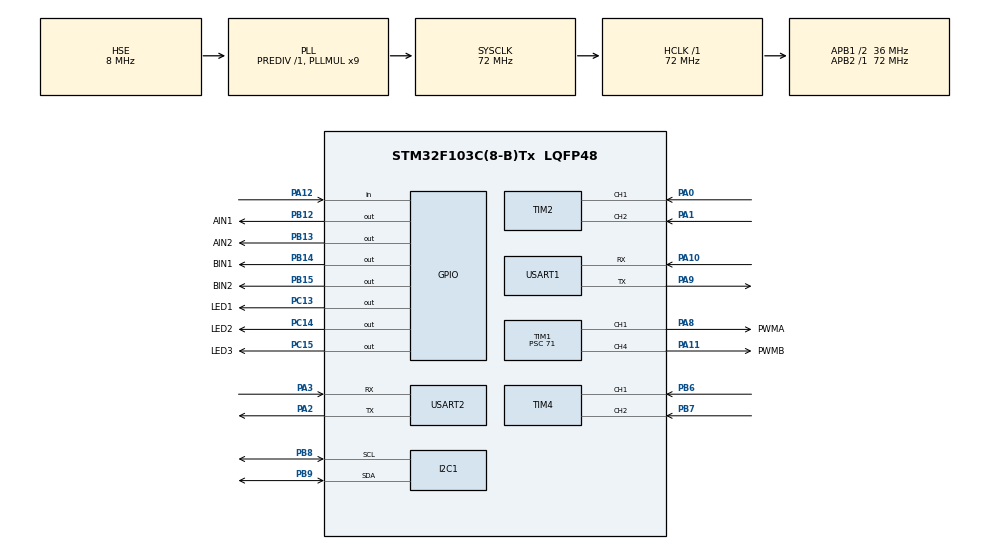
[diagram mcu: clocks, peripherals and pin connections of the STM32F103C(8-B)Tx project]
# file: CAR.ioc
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Mcu.Family=STM32F1
Mcu.Name=STM32F103C(8-B)Tx
Mcu.Package=LQFP48
NVIC.PriorityGroup=NVIC_PRIORITYGROUP_4
NVIC.TIM2_IRQn=true\:3\:0\:true\:false\:true\:true\:true
NVIC.TIM3_IRQn=true\:1\:0\:true\:false\:true\:true\:true
NVIC.TIM4_IRQn=true\:3\:0\:true\:false\:true\:true\:true
PA0-WKUP.Signal=S_TIM2_CH1_ETR
PA1.Signal=S_TIM2_CH2
PA10.Mode=Asynchronous
PA10.Signal=USART1_RX
PA11.GPIO_Label=PWMB
PA11.Signal=S_TIM1_CH4
PA12.Signal=GPIO_Input
PA13.Mode=Serial_Wire
PA13.Signal=SYS_JTMS-SWDIO
PA14.Mode=Serial_Wire
PA14.Signal=SYS_JTCK-SWCLK
PA2.Mode=Asynchronous
PA2.Signal=USART2_TX
PA3.Mode=Asynchronous
PA3.Signal=USART2_RX
PA8.GPIO_Label=PWMA
PA8.Signal=S_TIM1_CH1
PA9.Mode=Asynchronous
PA9.Signal=USART1_TX
PB12.GPIO_Label=AIN1
PB12.GPIO_Speed=GPIO_SPEED_FREQ_MEDIUM
PB12.Signal=GPIO_Output
PB13.GPIO_Label=AIN2
PB13.GPIO_Speed=GPIO_SPEED_FREQ_MEDIUM
PB13.Signal=GPIO_Output
PB14.GPIO_Label=BIN1
PB14.GPIO_Speed=GPIO_SPEED_FREQ_MEDIUM
PB14.Signal=GPIO_Output
PB15.GPIO_Label=BIN2
PB15.Signal=GPIO_Output
PB6.Signal=S_TIM4_CH1
PB7.Signal=S_TIM4_CH2
PB8.Mode=I2C
PB8.Signal=I2C1_SCL
PB9.Mode=I2C
PB9.Signal=I2C1_SDA
PC13-TAMPER-RTC.GPIO_Label=LED1
PC13-TAMPER-RTC.GPIO_PuPd=GPIO_PULLDOWN
PC13-TAMPER-RTC.Signal=GPIO_Output
PC14-OSC32_IN.GPIO_Label=LED2
PC14-OSC32_IN.GPIO_PuPd=GPIO_PULLDOWN
PC14-OSC32_IN.Signal=GPIO_Output
PC15-OSC32_OUT.GPIO_Label=LED3
PC15-OSC32_OUT.GPIO_PuPd=GPIO_PULLDOWN
PC15-OSC32_OUT.Signal=GPIO_Output
PD0-OSC_IN.Mode=HSE-External-Oscillator
PD0-OSC_IN.Signal=RCC_OSC_IN
PD1-OSC_OUT.Mode=HSE-External-Oscillator
PD1-OSC_OUT.Signal=RCC_OSC_OUT
ProjectManager.HeapSize=0x200
ProjectManager.StackSize=0x400
ProjectManager.TargetToolchain=MDK-ARM V5.32
RCC.AHBFreq_Value=72000000
RCC.APB1CLKDivider=RCC_HCLK_DIV2
RCC.APB1Freq_Value=36000000
RCC.APB1TimFreq_Value=72000000
RCC.APB2Freq_Value=72000000
RCC.APB2TimFreq_Value=72000000
RCC.HCLKFreq_Value=72000000
RCC.PLLMUL=RCC_PLL_MUL9
RCC.PLLSourceVirtual=RCC_PLLSOURCE_HSE
RCC.SYSCLKFreq_VALUE=72000000
RCC.SYSCLKSource=RCC_SYSCLKSOURCE_PLLCLK
RCC.USBFreq_Value=72000000
SH.S_TIM1_CH1.0=TIM1_CH1,PWM Generation1 CH1
SH.S_TIM1_CH4.0=TIM1_CH4,PWM Generation4 CH4
SH.S_TIM2_CH1_ETR.0=TIM2_CH1,Encoder_Interface
SH.S_TIM2_CH2.0=TIM2_CH2,Encoder_Interface
SH.S_TIM4_CH1.0=TIM4_CH1,Encoder_Interface
SH.S_TIM4_CH2.0=TIM4_CH2,Encoder_Interface
TIM1.Channel-PWM\ Generation1\ CH1=TIM_CHANNEL_1
TIM1.Channel-PWM\ Generation4\ CH4=TIM_CHANNEL_4
TIM1.Period=4999
TIM1.Prescaler=71
TIM2.EncoderMode=TIM_ENCODERMODE_TI12
TIM2.IC1Filter=10
TIM2.IC2Filter=10
TIM3.AutoReloadPreload=TIM_AUTORELOAD_PRELOAD_ENABLE
TIM3.Period=4999
TIM3.Prescaler=71
TIM4.EncoderMode=TIM_ENCODERMODE_TI12
TIM4.IC1Filter=10
TIM4.IC2Filter=10
USART1.VirtualMode=VM_ASYNC
USART2.VirtualMode=VM_ASYNC
VP_TIM1_VS_ClockSourceINT.Mode=Internal
VP_TIM3_VS_ClockSourceINT.Mode=Internal
board=custom

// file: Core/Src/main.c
/* USER CODE BEGIN Header */
/**
  ******************************************************************************
  * @file           : main.c
  * @brief          : Main program body
  ******************************************************************************
  * @attention
  *
  * Copyright (c) 2023 STMicroelectronics.
  * All rights reserved.
  *
  * This software is licensed under terms that can be found in the LICENSE file
  * in the root directory of this software component.
  * If no LICENSE file comes with this software, it is provided AS-IS.
  *
  ******************************************************************************
  */
/* USER CODE END Header */
#include "main.h"
#include "i2c.h"
#include "tim.h"
#include "usart.h"
#include "gpio.h"

/* USER CODE BEGIN PTD */

 int Encode_Left=0;			//定义左轮编码器读取值变量，更改会导致错误
 int Encode_Right=0;			//定义右轮编码器读取值变量，更改会导致错误
 int Encode_Left_ALL=0;		//定义左轮编码器累加值
 int Encode_Right_ALL=0;		//定义右轮编码器累加值
 int	Encode_Speed=0;			//定义通过编码器获取的小车前进速度,大于0前进速度，小于0后退速度
 int	Encode_Spin_Speed=0;	//通过编码器获取的小车旋转速度，大于右转速度，小于0左转速度

/* USER CODE END PTD */

void SystemClock_Config(void);

int main(void)
{

  /* MCU Configuration--------------------------------------------------------*/

  /* Reset of all peripherals, Initializes the Flash interface and the Systick. */
  HAL_Init();

  /* Configure the system clock */
  SystemClock_Config();

  /* Initialize all configured peripherals */
  MX_GPIO_Init();
  MX_TIM1_Init();
  MX_TIM2_Init();
  MX_TIM3_Init();
  MX_TIM4_Init();
  MX_USART1_UART_Init();
  MX_USART2_UART_Init();
  MX_I2C1_Init();
  /* USER CODE BEGIN 2 */
  set_motor_enable();
	CarTurnRight();

  /* USER CODE END 2 */

  /* Infinite loop */
  while (1)
  {

  }
}

void SystemClock_Config(void)
{
  RCC_OscInitTypeDef RCC_OscInitStruct = {0};
  RCC_ClkInitTypeDef RCC_ClkInitStruct = {0};

  /** Initializes the RCC Oscillators according to the specified parameters
  * in the RCC_OscInitTypeDef structure.
  */
  RCC_OscInitStruct.OscillatorType = RCC_OSCILLATORTYPE_HSE;
  RCC_OscInitStruct.HSEState = RCC_HSE_ON;
  RCC_OscInitStruct.HSEPredivValue = RCC_HSE_PREDIV_DIV1;
  RCC_OscInitStruct.HSIState = RCC_HSI_ON;
  RCC_OscInitStruct.PLL.PLLState = RCC_PLL_ON;
  RCC_OscInitStruct.PLL.PLLSource = RCC_PLLSOURCE_HSE;
  RCC_OscInitStruct.PLL.PLLMUL = RCC_PLL_MUL9;
  if (HAL_RCC_OscConfig(&RCC_OscInitStruct) != HAL_OK)
  {
    Error_Handler();
  }
  /** Initializes the CPU, AHB and APB buses clocks
  */
  RCC_ClkInitStruct.ClockType = RCC_CLOCKTYPE_HCLK|RCC_CLOCKTYPE_SYSCLK
                              |RCC_CLOCKTYPE_PCLK1|RCC_CLOCKTYPE_PCLK2;
  RCC_ClkInitStruct.SYSCLKSource = RCC_SYSCLKSOURCE_PLLCLK;
  RCC_ClkInitStruct.AHBCLKDivider = RCC_SYSCLK_DIV1;
  RCC_ClkInitStruct.APB1CLKDivider = RCC_HCLK_DIV2;
  RCC_ClkInitStruct.APB2CLKDivider = RCC_HCLK_DIV1;

  if (HAL_RCC_ClockConfig(&RCC_ClkInitStruct, FLASH_LATENCY_2) != HAL_OK)
  {
    Error_Handler();
  }
}

void Error_Handler(void)
{
  __disable_irq();
  while (1)
  {
  }
}
